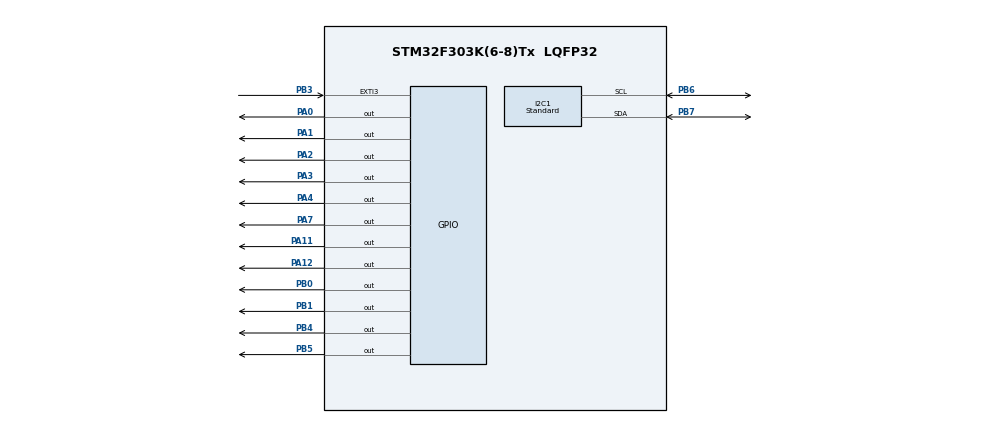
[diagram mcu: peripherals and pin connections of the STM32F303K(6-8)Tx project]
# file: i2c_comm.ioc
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I2C1.I2C_Speed_Mode=I2C_Standard
I2C1.OwnAddress=1
Mcu.Family=STM32F3
Mcu.Name=STM32F303K(6-8)Tx
Mcu.Package=LQFP32
NVIC.I2C1_EV_IRQn=true\:0\:0\:false\:false\:true\:true\:true
NVIC.PriorityGroup=NVIC_PRIORITYGROUP_4
PA0.GPIO_PuPd=GPIO_PULLUP
PA0.Signal=GPIO_Output
PA1.GPIO_PuPd=GPIO_PULLUP
PA1.Signal=GPIO_Output
PA11.GPIO_PuPd=GPIO_PULLUP
PA11.Signal=GPIO_Output
PA12.GPIO_PuPd=GPIO_PULLUP
PA12.Signal=GPIO_Output
PA2.GPIO_PuPd=GPIO_PULLUP
PA2.Signal=GPIO_Output
PA3.GPIO_PuPd=GPIO_PULLUP
PA3.Signal=GPIO_Output
PA4.GPIO_PuPd=GPIO_PULLUP
PA4.Signal=GPIO_Output
PA7.GPIO_PuPd=GPIO_PULLUP
PA7.Signal=GPIO_Output
PB0.GPIO_PuPd=GPIO_PULLUP
PB0.Signal=GPIO_Output
PB1.GPIO_PuPd=GPIO_PULLUP
PB1.Signal=GPIO_Output
PB3.GPIO_PuPd=GPIO_PULLDOWN
PB3.Signal=GPXTI3
PB4.GPIO_PuPd=GPIO_PULLUP
PB4.Signal=GPIO_Output
PB5.GPIO_PuPd=GPIO_PULLUP
PB5.Signal=GPIO_Output
PB6.GPIO_Pu=GPIO_PULLUP
PB6.Mode=I2C
PB6.Signal=I2C1_SCL
PB7.GPIO_Pu=GPIO_PULLUP
PB7.Mode=I2C
PB7.Signal=I2C1_SDA
ProjectManager.HeapSize=0x200
ProjectManager.StackSize=0x400
ProjectManager.TargetToolchain=STM32CubeIDE
RCC.AHBFreq_Value=8000000
RCC.APB1Freq_Value=8000000
RCC.APB2Freq_Value=8000000
RCC.CortexFreq_Value=8000000
RCC.HSE_VALUE=8000000
RCC.HSI_VALUE=8000000
RCC.SYSCLKFreq_VALUE=8000000
board=custom

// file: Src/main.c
/* USER CODE BEGIN Header */
/**
  ******************************************************************************
  * @file           : main.c
  * @brief          : Main program body
  ******************************************************************************
  * @attention
  *
  * <h2><center>&copy; Copyright (c) 2019 STMicroelectronics.
  * All rights reserved.</center></h2>
  *
  * This software component is licensed by ST under BSD 3-Clause license,
  * the "License"; You may not use this file except in compliance with the
  * License. You may obtain a copy of the License at:
  *                        opensource.org/licenses/BSD-3-Clause
  *
  ******************************************************************************
  */
/* USER CODE END Header */
#include "main.h"
#include "i2c.h"
#include "gpio.h"
#include "lis3mdltr.h"
#include "lsm6ds0.h"

uint8_t temp = 0;
float mag[3], acc[3];
uint8_t count=0;

void SystemClock_Config(void);
/* USER CODE BEGIN PFP */
void led(float num);
void display(int A,int B,int C,int D);
/* USER CODE END PFP */

int main(void)
{

  /* MCU Configuration--------------------------------------------------------*/

  /* Reset of all peripherals, Initializes the Flash interface and the Systick. */

  LL_APB2_GRP1_EnableClock(LL_APB2_GRP1_PERIPH_SYSCFG);
  LL_APB1_GRP1_EnableClock(LL_APB1_GRP1_PERIPH_PWR);

  NVIC_SetPriorityGrouping(NVIC_PRIORITYGROUP_4);

  /* System interrupt init*/

  /* Configure the system clock */
  SystemClock_Config();

  /* Initialize all configured peripherals */
  MX_GPIO_Init();
  MX_I2C1_Init();
  /* USER CODE BEGIN 2 */
  lis3mdl_init();
  /* USER CODE END 2 */
  lsm6ds0_init();
  /* Infinite loop */
  /* USER CODE BEGIN WHILE */
  while (1)
  {

	  //os			   x      y        z

	  lsm6ds0_get_acc(acc, (acc+1), (acc+2));
	  lis3mdl_get_mag(mag, (mag+1), (mag+2));
	  temp=lis3mdl_get_temp();//这些是得到的数据
	  LL_mDelay(50);
	  float Cloud[]={acc[0],acc[1],acc[2],mag[0],mag[1],mag[2],temp};
	  led(Cloud[count]);
	  //GPIO IDR, read input from pin 6
	  if(!(*((volatile uint32_t *)((uint32_t)(0x48000400 + 0x10U))) & (1 << 3)))
	  {
           count++;
           if(count==7)
           {
        	   count=0;
           }
	  }

  }
}

void led(float num)
{
	int A,B,C,D;

	A=(num/10);
	B=(num-A*10);
	C=((num-A*10-B)*100/10);
	D=((num-A*10-B)*100-C*10);
	display(A,B,C,D);
}
void display(int A,int B,int C,int D)
{
	GPIOA_ODR_REG|=(1<<7);//PA7
	 LED_ON(A);//点亮数字A
	GPIOA_ODR_REG|=(1<<12);//PA12
	LED2_ON(B);//点亮数字B,有小数点

	GPIOA_ODR_REG|=(1<<4);//PA4
	LED_ON(C);//点亮数字B

	GPIOB_ODR_REG|=(1<<4);//PB0
	LED_ON(D);//点亮数字D
}
void SystemClock_Config(void)
{
  LL_FLASH_SetLatency(LL_FLASH_LATENCY_0);
  while(LL_FLASH_GetLatency()!= LL_FLASH_LATENCY_0)
  {
  }
  LL_RCC_HSI_Enable();

   /* Wait till HSI is ready */
  while(LL_RCC_HSI_IsReady() != 1)
  {

  }
  LL_RCC_HSI_SetCalibTrimming(16);
  LL_RCC_SetAHBPrescaler(LL_RCC_SYSCLK_DIV_1);
  LL_RCC_SetAPB1Prescaler(LL_RCC_APB1_DIV_1);
  LL_RCC_SetAPB2Prescaler(LL_RCC_APB2_DIV_1);
  LL_RCC_SetSysClkSource(LL_RCC_SYS_CLKSOURCE_HSI);

   /* Wait till System clock is ready */
  while(LL_RCC_GetSysClkSource() != LL_RCC_SYS_CLKSOURCE_STATUS_HSI)
  {

  }
  LL_Init1msTick(8000000);
  LL_SetSystemCoreClock(8000000);
  LL_RCC_SetI2CClockSource(LL_RCC_I2C1_CLKSOURCE_HSI);
}

void Error_Handler(void)
{
}

/************************ (C) COPYRIGHT STMicroelectronics *****END OF FILE****/
